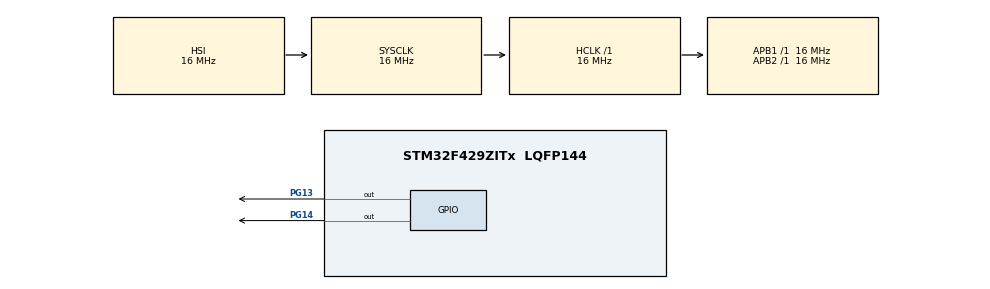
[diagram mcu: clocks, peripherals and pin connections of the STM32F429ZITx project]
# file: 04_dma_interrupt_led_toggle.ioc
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Dma.MEMTOMEM.0.Direction=DMA_MEMORY_TO_MEMORY
Dma.MEMTOMEM.0.FIFOMode=DMA_FIFOMODE_ENABLE
Dma.MEMTOMEM.0.FIFOThreshold=DMA_FIFO_THRESHOLD_FULL
Dma.MEMTOMEM.0.Instance=DMA2_Stream0
Dma.MEMTOMEM.0.MemBurst=DMA_MBURST_SINGLE
Dma.MEMTOMEM.0.MemDataAlignment=DMA_MDATAALIGN_BYTE
Dma.MEMTOMEM.0.MemInc=DMA_MINC_ENABLE
Dma.MEMTOMEM.0.Mode=DMA_NORMAL
Dma.MEMTOMEM.0.PeriphBurst=DMA_PBURST_SINGLE
Dma.MEMTOMEM.0.PeriphDataAlignment=DMA_PDATAALIGN_BYTE
Dma.MEMTOMEM.0.PeriphInc=DMA_PINC_ENABLE
Dma.MEMTOMEM.0.Priority=DMA_PRIORITY_LOW
Dma.Request0=MEMTOMEM
Mcu.Family=STM32F4
Mcu.Name=STM32F429ZITx
Mcu.Package=LQFP144
NVIC.DMA2_Stream0_IRQn=true\:0\:0\:false\:false\:true\:true
NVIC.PriorityGroup=NVIC_PRIORITYGROUP_4
PG13.Signal=GPIO_Output
PG14.Signal=GPIO_Output
ProjectManager.HeapSize=0x200
ProjectManager.StackSize=0x400
ProjectManager.TargetToolchain=SW4STM32
RCC.AHBFreq_Value=16000000
RCC.APB1Freq_Value=16000000
RCC.APB2Freq_Value=16000000
RCC.CortexFreq_Value=16000000
RCC.HSE_VALUE=25000000
RCC.HSI_VALUE=16000000
RCC.LSE_VALUE=32768
RCC.SYSCLKFreq_VALUE=16000000
RCC.VCOOutputFreq_Value=192000000
board=custom

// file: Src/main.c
/**
  ******************************************************************************
  * @file           : main.c
  * @brief          : Main program body
  ******************************************************************************
  ** This notice applies to any and all portions of this file
  * that are not between comment pairs USER CODE BEGIN and
  * USER CODE END. Other portions of this file, whether
  * inserted by the user or by software development tools
  * are owned by their respective copyright owners.
  *
  * COPYRIGHT(c) 2020 STMicroelectronics
  *
  * Redistribution and use in source and binary forms, with or without modification,
  * are permitted provided that the following conditions are met:
  *   1. Redistributions of source code must retain the above copyright notice,
  *      this list of conditions and the following disclaimer.
  *   2. Redistributions in binary form must reproduce the above copyright notice,
  *      this list of conditions and the following disclaimer in the documentation
  *      and/or other materials provided with the distribution.
  *   3. Neither the name of STMicroelectronics nor the names of its contributors
  *      may be used to endorse or promote products derived from this software
  *      without specific prior written permission.
  *
  * THIS SOFTWARE IS PROVIDED BY THE COPYRIGHT HOLDERS AND CONTRIBUTORS "AS IS"
  * AND ANY EXPRESS OR IMPLIED WARRANTIES, INCLUDING, BUT NOT LIMITED TO, THE
  * IMPLIED WARRANTIES OF MERCHANTABILITY AND FITNESS FOR A PARTICULAR PURPOSE ARE
  * DISCLAIMED. IN NO EVENT SHALL THE COPYRIGHT HOLDER OR CONTRIBUTORS BE LIABLE
  * FOR ANY DIRECT, INDIRECT, INCIDENTAL, SPECIAL, EXEMPLARY, OR CONSEQUENTIAL
  * DAMAGES (INCLUDING, BUT NOT LIMITED TO, PROCUREMENT OF SUBSTITUTE GOODS OR
  * SERVICES; LOSS OF USE, DATA, OR PROFITS; OR BUSINESS INTERRUPTION) HOWEVER
  * CAUSED AND ON ANY THEORY OF LIABILITY, WHETHER IN CONTRACT, STRICT LIABILITY,
  * OR TORT (INCLUDING NEGLIGENCE OR OTHERWISE) ARISING IN ANY WAY OUT OF THE USE
  * OF THIS SOFTWARE, EVEN IF ADVISED OF THE POSSIBILITY OF SUCH DAMAGE.
  *
  ******************************************************************************
  */
#include "main.h"
#include "stm32f4xx_hal.h"

/* USER CODE BEGIN Includes */
#include <stdint.h>
/* USER CODE END Includes */

DMA_HandleTypeDef hdma_memtomem_dma2_stream0;

/* USER CODE BEGIN PV */
/* Private variables ---------------------------------------------------------*/

/* USER CODE END PV */

void SystemClock_Config(void);
static void MX_GPIO_Init(void);
static void MX_DMA_Init(void);

/* USER CODE BEGIN PFP */
/* Private function prototypes -----------------------------------------------*/

/* USER CODE END PFP */

/* USER CODE BEGIN 0 */
uint8_t idx;
volatile uint8_t dma_flag;
uint16_t led_data[2] = {0xffff, 0x0000};

void dma_full_callback(DMA_HandleTypeDef *_hdma)
{
	dma_flag = 1;
}
/* USER CODE END 0 */

int main(void)
{

  /* MCU Configuration----------------------------------------------------------*/

  /* Reset of all peripherals, Initializes the Flash interface and the Systick. */
  HAL_Init();

  /* Configure the system clock */
  SystemClock_Config();

  /* Initialize all configured peripherals */
  MX_GPIO_Init();
  MX_DMA_Init();
  /* USER CODE BEGIN 2 */
  // HAL_DMA_RegisterCallback(DMA_HandleTypeDef *hdma, HAL_DMA_CallbackIDTypeDef CallbackID, void (* pCallback)(DMA_HandleTypeDef *_hdma));

  HAL_DMA_RegisterCallback(&hdma_memtomem_dma2_stream0, HAL_DMA_XFER_CPLT_CB_ID, dma_full_callback);
  HAL_DMA_Start_IT(&hdma_memtomem_dma2_stream0, (uint32_t)&led_data[idx], (uint32_t)&GPIOG->ODR, 2);

  /* USER CODE END 2 */

  /* Infinite loop */
  while (1)
  {

  /* USER CODE BEGIN 3 */
	  if(dma_flag) {
		HAL_Delay(500);
		idx = (idx + 1) % 2;
		HAL_DMA_Start_IT(&hdma_memtomem_dma2_stream0, (uint32_t)&led_data[idx], (uint32_t)&GPIOG->ODR, 2);
		dma_flag = 0;
	  }

  }
  /* USER CODE END 3 */

}

void SystemClock_Config(void)
{

  RCC_OscInitTypeDef RCC_OscInitStruct;
  RCC_ClkInitTypeDef RCC_ClkInitStruct;

    /**Configure the main internal regulator output voltage
    */
  __HAL_RCC_PWR_CLK_ENABLE();

  __HAL_PWR_VOLTAGESCALING_CONFIG(PWR_REGULATOR_VOLTAGE_SCALE3);

    /**Initializes the CPU, AHB and APB busses clocks
    */
  RCC_OscInitStruct.OscillatorType = RCC_OSCILLATORTYPE_HSI;
  RCC_OscInitStruct.HSIState = RCC_HSI_ON;
  RCC_OscInitStruct.HSICalibrationValue = 16;
  RCC_OscInitStruct.PLL.PLLState = RCC_PLL_NONE;
  if (HAL_RCC_OscConfig(&RCC_OscInitStruct) != HAL_OK)
  {
    _Error_Handler(__FILE__, __LINE__);
  }

    /**Initializes the CPU, AHB and APB busses clocks
    */
  RCC_ClkInitStruct.ClockType = RCC_CLOCKTYPE_HCLK|RCC_CLOCKTYPE_SYSCLK
                              |RCC_CLOCKTYPE_PCLK1|RCC_CLOCKTYPE_PCLK2;
  RCC_ClkInitStruct.SYSCLKSource = RCC_SYSCLKSOURCE_HSI;
  RCC_ClkInitStruct.AHBCLKDivider = RCC_SYSCLK_DIV1;
  RCC_ClkInitStruct.APB1CLKDivider = RCC_HCLK_DIV1;
  RCC_ClkInitStruct.APB2CLKDivider = RCC_HCLK_DIV1;

  if (HAL_RCC_ClockConfig(&RCC_ClkInitStruct, FLASH_LATENCY_0) != HAL_OK)
  {
    _Error_Handler(__FILE__, __LINE__);
  }

    /**Configure the Systick interrupt time
    */
  HAL_SYSTICK_Config(HAL_RCC_GetHCLKFreq()/1000);

    /**Configure the Systick
    */
  HAL_SYSTICK_CLKSourceConfig(SYSTICK_CLKSOURCE_HCLK);

  /* SysTick_IRQn interrupt configuration */
  HAL_NVIC_SetPriority(SysTick_IRQn, 0, 0);
}

static void MX_DMA_Init(void)
{
  /* DMA controller clock enable */
  __HAL_RCC_DMA2_CLK_ENABLE();

  /* Configure DMA request hdma_memtomem_dma2_stream0 on DMA2_Stream0 */
  hdma_memtomem_dma2_stream0.Instance = DMA2_Stream0;
  hdma_memtomem_dma2_stream0.Init.Channel = DMA_CHANNEL_0;
  hdma_memtomem_dma2_stream0.Init.Direction = DMA_MEMORY_TO_MEMORY;
  hdma_memtomem_dma2_stream0.Init.PeriphInc = DMA_PINC_ENABLE;
  hdma_memtomem_dma2_stream0.Init.MemInc = DMA_MINC_ENABLE;
  hdma_memtomem_dma2_stream0.Init.PeriphDataAlignment = DMA_PDATAALIGN_BYTE;
  hdma_memtomem_dma2_stream0.Init.MemDataAlignment = DMA_MDATAALIGN_BYTE;
  hdma_memtomem_dma2_stream0.Init.Mode = DMA_NORMAL;
  hdma_memtomem_dma2_stream0.Init.Priority = DMA_PRIORITY_LOW;
  hdma_memtomem_dma2_stream0.Init.FIFOMode = DMA_FIFOMODE_ENABLE;
  hdma_memtomem_dma2_stream0.Init.FIFOThreshold = DMA_FIFO_THRESHOLD_FULL;
  hdma_memtomem_dma2_stream0.Init.MemBurst = DMA_MBURST_SINGLE;
  hdma_memtomem_dma2_stream0.Init.PeriphBurst = DMA_PBURST_SINGLE;
  if (HAL_DMA_Init(&hdma_memtomem_dma2_stream0) != HAL_OK)
  {
    _Error_Handler(__FILE__, __LINE__);
  }

  /* DMA interrupt init */
  /* DMA2_Stream0_IRQn interrupt configuration */
  HAL_NVIC_SetPriority(DMA2_Stream0_IRQn, 0, 0);
  HAL_NVIC_EnableIRQ(DMA2_Stream0_IRQn);

}

/** Configure pins as
        * Analog
        * Input
        * Output
        * EVENT_OUT
        * EXTI
*/
static void MX_GPIO_Init(void)
{

  GPIO_InitTypeDef GPIO_InitStruct;

  /* GPIO Ports Clock Enable */
  __HAL_RCC_GPIOG_CLK_ENABLE();

  /*Configure GPIO pin Output Level */
  HAL_GPIO_WritePin(GPIOG, GPIO_PIN_13|GPIO_PIN_14, GPIO_PIN_RESET);

  /*Configure GPIO pins : PG13 PG14 */
  GPIO_InitStruct.Pin = GPIO_PIN_13|GPIO_PIN_14;
  GPIO_InitStruct.Mode = GPIO_MODE_OUTPUT_PP;
  GPIO_InitStruct.Pull = GPIO_NOPULL;
  GPIO_InitStruct.Speed = GPIO_SPEED_FREQ_LOW;
  HAL_GPIO_Init(GPIOG, &GPIO_InitStruct);

}

void _Error_Handler(char *file, int line)
{
  while(1)
  {
  }
}

/************************ (C) COPYRIGHT STMicroelectronics *****END OF FILE****/
